# STM32L562 register map
File version: 1.1
Registers are 32-bit, read-write, reset 0x0 unless marked. A register's access mark holds for its fields unless they carry their own. Offsets are from the block's base; lines under a group give offsets from that group; [hi:lo] are bit positions; {n}, {i} and the like mark numbered series; 'fields as' and 'values as' point back to an identical list; <NAME> marks a mode.

## Memory map
0x420C5000 OTFDEC1 size 0x400 — On-The-Fly Decryption engine

## Interrupts
108 OTFDEC1 — OTFDEC1 secure global interrupt

## OTFDEC1 — On-The-Fly Decryption engine
Base 0x420C5000
0x00 CR — OTFDEC control register
  [0] ENC — Encryption mode bit
{0x20+0x30*i} R[{i}] (i=0..3) group
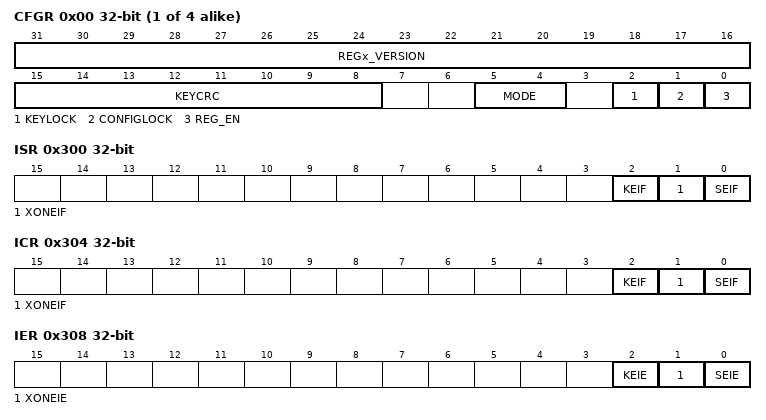
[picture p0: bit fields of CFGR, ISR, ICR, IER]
  0x00 CFGR — OTFDEC region x configuration register
    [31:16] REGx_VERSION — region firmware version
    [15:8] KEYCRC ro — region key 8-bit CRC
    [5:4] MODE — operating mode
    [2] KEYLOCK — region key lock
    [1] CONFIGLOCK — region config lock
    [0] REG_EN — region on-the-fly decryption enable
  0x04 STARTADDR — OTFDEC region x start address register
    [31:0] REGx_START_ADDR — Region AXI start address
  0x08 ENDADDR — OTFDEC region x end address register
    [31:0] REGx_END_ADDR — Region AXI end address
  {0xC+4j} NONCER[{j}] (j=0..1)
    [31:0] REGx_NONCE
  {0x14+4j} KEYR[{j}] (j=0..3)
    [31:0] REGx_KEY
0x300 ISR ro — OTFDEC interrupt status register
  [2] KEIF — Key Error Interrupt Flag status
  [1] XONEIF — Execute-only execute-Never Error Interrupt Flag status
  [0] SEIF — Security Error Interrupt Flag status
0x304 ICR wo — OTFDEC interrupt clear register
  [2] KEIF
  [1] XONEIF — Execute-only execute-Never Error Interrupt Flag clear
  [0] SEIF
0x308 IER — OTFDEC interrupt enable register
  [2] KEIE
  [1] XONEIE
  [0] SEIE — Security Error Interrupt Enable
